# STM32WL3R register map
File version: 0.3
CPU: CM0+ r0p0, little endian, MPU, no FPU, 4 interrupt priority bits
Registers are 32-bit, read-write, reset 0x0 unless marked. A register's access mark holds for its fields unless they carry their own. Offsets are from the block's base; [hi:lo] are bit positions.

## LPUART — LPUART address block description
Base 0x41005000
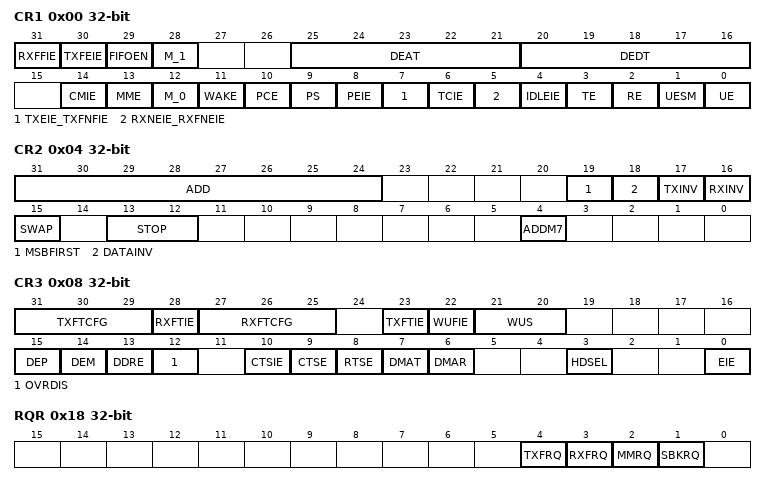
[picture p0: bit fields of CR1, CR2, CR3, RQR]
0x00 CR1
  [31] RXFFIE — RXFFIE :RXFIFO Full interrupt enable
  [30] TXFEIE — TXFEIE :TXFIFO empty interrupt enable
  [29] FIFOEN — FIFOEN :FIFO mode enable
  [28] M_1 — Word length
  [25:21] DEAT — DEAT[4:0]: Driver Enable assertion time
  [20:16] DEDT — DEDT[4:0]: Driver Enable deassertion time
  [14] CMIE — CMIE: Character match interrupt enable
  [13] MME — MME: Mute mode enable
  [12] M_0 — M0: Word length
  [11] WAKE — WAKE: Receiver wakeup method
  [10] PCE — PCE: Parity control enable
  [9] PS — PS: Parity selection
  [8] PEIE — PEIE: PE interrupt enable
  [7] TXEIE_TXFNFIE — TXEIE/TXFNFIE: Transmit data regsiter empty/TXFIFO not full interrupt enable
  [6] TCIE — TCIE: Transmission complete interrupt enable
  [5] RXNEIE_RXFNEIE — RXNEIE/RXFNEIE: Receive data register not empty/RXFIFO not empty interrupt enable
  [4] IDLEIE — IDLEIE: IDLE interrupt enable
  [3] TE — TE: Transmitter enable
  [2] RE — RE: Receiver enable
  [1] UESM — UESM: LPUART enable in Stop mode
  [0] UE — UE: USART enable
0x04 CR2
  [31:24] ADD — ADD[7:0]: Address of the USART node
  [19] MSBFIRST — MSBFIRST: Most significant bit first
  [18] DATAINV — DATAINV: Binary data inversion
  [17] TXINV — TXINV: TX pin active level inversion
  [16] RXINV — RXINV: RX pin active level inversion
  [15] SWAP — SWAP: Swap TX/RX pins
  [13:12] STOP — STOP[1:0]: STOP bits
  [4] ADDM7 — ADDM7:7-bit Address Detection/4-bit Address Detection
0x08 CR3
  [31:29] TXFTCFG — TXFTCFG: TXFIFO threshold configuration
  [28] RXFTIE — RXFTIE: RXFIFO threshold interrupt enable
  [27:25] RXFTCFG — RXFTCFG: Receive FIFO threshold configuration
  [23] TXFTIE — TXFTIE: TXFIFO threshold interrupt enable
  [22] WUFIE — WUFIE: Wakeup from Stop mode interrupt enable
  [21:20] WUS — WUS[1:0]: Wakeup from Stop mode interrupt flag selection
  [15] DEP — DEP: Driver enable polarity selection
  [14] DEM — DEM: Driver enable mode
  [13] DDRE — DDRE: DMA Disable on Reception Error
  [12] OVRDIS — OVRDIS: Overrun Disable
  [10] CTSIE — CTSIE: CTS interrupt enable
  [9] CTSE — CTSE: CTS enable
  [8] RTSE — RTSE: RTS enable
  [7] DMAT — DMAT: DMA enable transmitter
  [6] DMAR — DMAR: DMA enable receiver
  [3] HDSEL — HDSEL: Half-duplex selection
  [0] EIE — EIE: Error interrupt enable
0x0C BRR
  [19:0] BRR — BRR[19:0]
0x18 RQR
  [4] TXFRQ wo — TXFRQ: Transmit data flush request
  [3] RXFRQ wo — RXFRQ: Receive data flush request
  [2] MMRQ wo — MMRQ: Mute mode request
  [1] SBKRQ wo — SBKRQ: Send break request
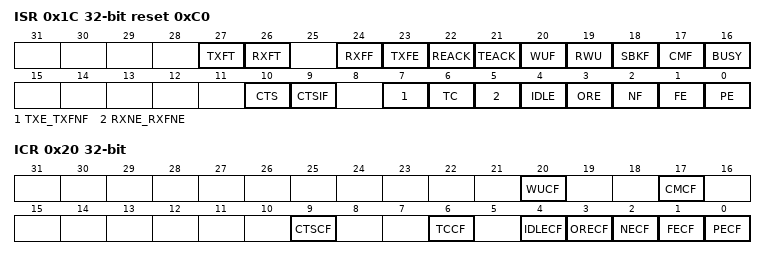
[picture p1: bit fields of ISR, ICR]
0x1C ISR ro reset 0xC0
  [27] TXFT — TXFT: TXFIFO threshold flag
  [26] RXFT — RXFT: RXFIFO threshold flag
  [24] RXFF — RXFF: RXFIFO Full
  [23] TXFE — TXFE: TXFIFO Empty
  [22] REACK — REACK: Receive enable acknowledge flag
  [21] TEACK — TEACK: Transmit enable acknowledge flag
  [20] WUF — WUF: Wakeup from Stop mode flag
  [19] RWU — RWU: Receiver wakeup from Mute mode
  [18] SBKF — SBKF: Send break flag
  [17] CMF — CMF: Character match flag
  [16] BUSY — BUSY: Busy flag
  [10] CTS — CTS: CTS flag
  [9] CTSIF — CTSIF: CTS interrupt flag
  [7] TXE_TXFNF — TXE/TXFNF: Transmit data register empty/TXFIFO not full
  [6] TC — TC: Transmission complete
  [5] RXNE_RXFNE — RXNE/RXFNE:Read data register not empty/RXFIFO not empty
  [4] IDLE — IDLE: Idle line detected
  [3] ORE — ORE: Overrun error
  [2] NF — NF: START bit Noise detection flag
  [1] FE — FE: Framing error
  [0] PE — PE: Parity error
0x20 ICR
  [20] WUCF wo — WUCF: Wakeup from Stop mode clear flag
  [17] CMCF wo — CMCF: Character match clear flag
  [9] CTSCF wo — CTSCF: CTS clear flag
  [6] TCCF wo — TCCF: Transmission complete clear flag
  [4] IDLECF wo — IDLECF: Idle line detected clear flag
  [3] ORECF wo — ORECF: Overrun error clear flag
  [2] NECF wo — NECF: Noise detected clear flag
  [1] FECF wo — FECF: Framing error clear flag
  [0] PECF wo — PECF: Parity error clear flag
0x24 RDR ro
  [8:0] RDR — RDR[8:0]: Receive data value
0x28 TDR
  [8:0] TDR — TDR[8:0]: Transmit data value
0x2C PRESC
  [3:0] PRESCALER — PRESCALER[3:0]: Clock prescaler
